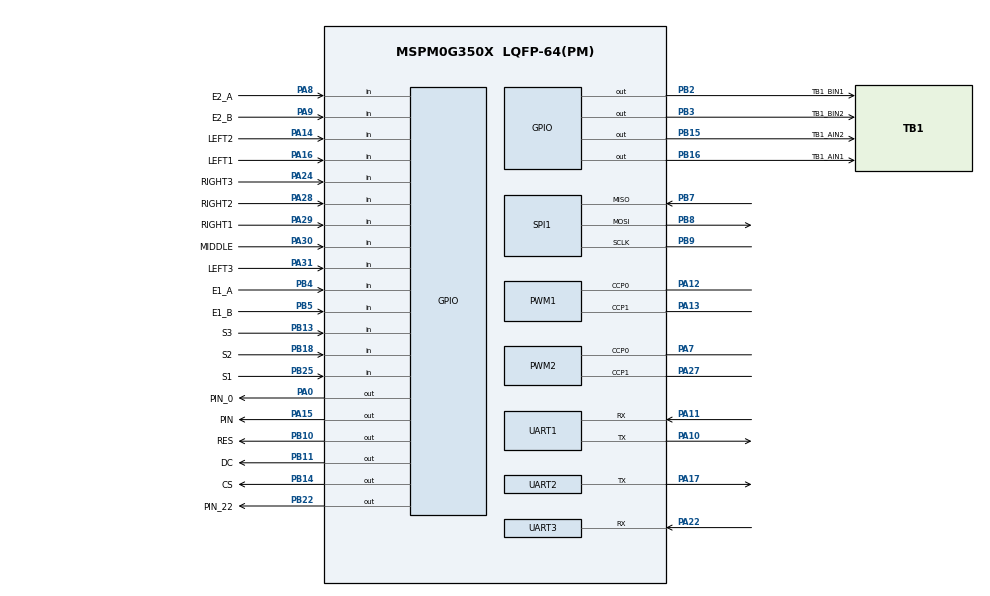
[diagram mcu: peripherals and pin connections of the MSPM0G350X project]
/**
 * @cliArgs --device "MSPM0G350X" --part "Default" --package "LQFP-64(PM)" --product "mspm0_sdk@2.05.01.01"
 * @versions {"tool":"1.24.0+4110"}
 */

/**
 * Import the modules used in this configuration.
 */
const GPIO    = scripting.addModule("/ti/driverlib/GPIO", {}, false);
const GPIO1   = GPIO.addInstance();
const GPIO2   = GPIO.addInstance();
const GPIO3   = GPIO.addInstance();
const GPIO4   = GPIO.addInstance();
const GPIO5   = GPIO.addInstance();
const GPIO6   = GPIO.addInstance();
const GPIO7   = GPIO.addInstance();
const GPIO8   = GPIO.addInstance();
const GPIO9   = GPIO.addInstance();
const PWM     = scripting.addModule("/ti/driverlib/PWM", {}, false);
const PWM1    = PWM.addInstance();
const PWM2    = PWM.addInstance();
const SPI     = scripting.addModule("/ti/driverlib/SPI", {}, false);
const SPI1    = SPI.addInstance();
const SYSCTL  = scripting.addModule("/ti/driverlib/SYSCTL");
const SYSTICK = scripting.addModule("/ti/driverlib/SYSTICK");
const TIMER   = scripting.addModule("/ti/driverlib/TIMER", {}, false);
const TIMER1  = TIMER.addInstance();
const TIMER2  = TIMER.addInstance();
const UART    = scripting.addModule("/ti/driverlib/UART", {}, false);
const UART1   = UART.addInstance();
const UART2   = UART.addInstance();
const UART3   = UART.addInstance();

/**
 * Write custom configuration values to the imported modules.
 */
const divider6       = system.clockTree["PLL_CLK2X_DIV"];
divider6.divideValue = 4;

const divider7       = system.clockTree["PLL_PDIV"];
divider7.divideValue = 2;

const divider9       = system.clockTree["UDIV"];
divider9.divideValue = 2;

const gate7  = system.clockTree["MFCLKGATE"];
gate7.enable = true;

const multiplier2         = system.clockTree["PLL_QDIV"];
multiplier2.multiplyValue = 10;

const mux8       = system.clockTree["HSCLKMUX"];
mux8.inputSelect = "HSCLKMUX_SYSPLL2X";

GPIO1.$name                         = "LED";
GPIO1.port                          = "PORTB";
GPIO1.associatedPins[0].$name       = "PIN_22";
GPIO1.associatedPins[0].ioStructure = "SD";
GPIO1.associatedPins[0].assignedPin = "22";
GPIO1.associatedPins[0].pin.$assign = "PB22";

const Board = scripting.addModule("/ti/driverlib/Board", {}, false);

GPIO2.$name                         = "OLED";
GPIO2.port                          = "PORTB";
GPIO2.associatedPins.create(3);
GPIO2.associatedPins[0].$name       = "RES";
GPIO2.associatedPins[0].assignedPin = "10";
GPIO2.associatedPins[0].pin.$assign = "PB10";
GPIO2.associatedPins[1].$name       = "DC";
GPIO2.associatedPins[1].assignedPin = "11\\";
GPIO2.associatedPins[1].pin.$assign = "PB11";
GPIO2.associatedPins[2].$name       = "CS";
GPIO2.associatedPins[2].assignedPin = "14";
GPIO2.associatedPins[2].pin.$assign = "PB14";

GPIO3.$name                              = "SW";
GPIO3.port                               = "PORTB";
GPIO3.associatedPins.create(3);
GPIO3.associatedPins[0].$name            = "S1";
GPIO3.associatedPins[0].direction        = "INPUT";
GPIO3.associatedPins[0].internalResistor = "PULL_UP";
GPIO3.associatedPins[0].assignedPin      = "25";
GPIO3.associatedPins[0].pin.$assign      = "PB25";
GPIO3.associatedPins[1].$name            = "S2";
GPIO3.associatedPins[1].direction        = "INPUT";
GPIO3.associatedPins[1].internalResistor = "PULL_UP";
GPIO3.associatedPins[1].assignedPin      = "18";
GPIO3.associatedPins[1].pin.$assign      = "PB18";
GPIO3.associatedPins[2].$name            = "S3";
GPIO3.associatedPins[2].direction        = "INPUT";
GPIO3.associatedPins[2].assignedPin      = "13";
GPIO3.associatedPins[2].internalResistor = "PULL_UP";
GPIO3.associatedPins[2].pin.$assign      = "PB13";

GPIO4.$name                         = "BUZZER";
GPIO4.port                          = "PORTA";
GPIO4.associatedPins[0].$name       = "PIN";
GPIO4.associatedPins[0].assignedPin = "15";
GPIO4.associatedPins[0].pin.$assign = "PA15";

GPIO5.$name                         = "TB6612_1";
GPIO5.port                          = "PORTB";
GPIO5.associatedPins.create(4);
GPIO5.associatedPins[0].$name       = "TB1_AIN2";
GPIO5.associatedPins[0].assignedPin = "15";
GPIO5.associatedPins[0].pin.$assign = "PB15";
GPIO5.associatedPins[1].$name       = "TB1_AIN1";
GPIO5.associatedPins[1].assignedPin = "16";
GPIO5.associatedPins[1].pin.$assign = "PB16";
GPIO5.associatedPins[2].$name       = "TB1_BIN1";
GPIO5.associatedPins[2].assignedPin = "2";
GPIO5.associatedPins[2].pin.$assign = "PB2";
GPIO5.associatedPins[3].$name       = "TB1_BIN2";
GPIO5.associatedPins[3].assignedPin = "3";
GPIO5.associatedPins[3].pin.$assign = "PB3";

GPIO6.$name                         = "Encoder1";
GPIO6.port                          = "PORTB";
GPIO6.associatedPins.create(2);
GPIO6.associatedPins[0].$name       = "E1_A";
GPIO6.associatedPins[0].direction   = "INPUT";
GPIO6.associatedPins[0].interruptEn = true;
GPIO6.associatedPins[0].polarity    = "RISE";
GPIO6.associatedPins[0].assignedPin = "4";
GPIO6.associatedPins[0].pin.$assign = "PB4";
GPIO6.associatedPins[1].$name       = "E1_B";
GPIO6.associatedPins[1].direction   = "INPUT";
GPIO6.associatedPins[1].assignedPin = "5";
GPIO6.associatedPins[1].interruptEn = true;
GPIO6.associatedPins[1].polarity    = "RISE";
GPIO6.associatedPins[1].pin.$assign = "PB5";

GPIO7.$name                         = "Encoder2";
GPIO7.port                          = "PORTA";
GPIO7.associatedPins.create(2);
GPIO7.associatedPins[0].$name       = "E2_A";
GPIO7.associatedPins[0].direction   = "INPUT";
GPIO7.associatedPins[0].assignedPin = "8";
GPIO7.associatedPins[0].interruptEn = true;
GPIO7.associatedPins[0].polarity    = "RISE";
GPIO7.associatedPins[0].pin.$assign = "PA8";
GPIO7.associatedPins[1].$name       = "E2_B";
GPIO7.associatedPins[1].direction   = "INPUT";
GPIO7.associatedPins[1].assignedPin = "9";
GPIO7.associatedPins[1].interruptEn = true;
GPIO7.associatedPins[1].polarity    = "RISE";
GPIO7.associatedPins[1].pin.$assign = "PA9";

GPIO8.$name                              = "GRAY";
GPIO8.port                               = "PORTA";
GPIO8.associatedPins.create(7);
GPIO8.associatedPins[0].$name            = "RIGHT2";
GPIO8.associatedPins[0].direction        = "INPUT";
GPIO8.associatedPins[0].internalResistor = "PULL_UP";
GPIO8.associatedPins[0].assignedPin      = "28";
GPIO8.associatedPins[0].pin.$assign      = "PA28";
GPIO8.associatedPins[1].$name            = "RIGHT1";
GPIO8.associatedPins[1].direction        = "INPUT";
GPIO8.associatedPins[1].internalResistor = "PULL_UP";
GPIO8.associatedPins[1].assignedPin      = "29";
GPIO8.associatedPins[1].pin.$assign      = "PA29";
GPIO8.associatedPins[2].$name            = "MIDDLE";
GPIO8.associatedPins[2].direction        = "INPUT";
GPIO8.associatedPins[2].internalResistor = "PULL_UP";
GPIO8.associatedPins[2].assignedPin      = "30";
GPIO8.associatedPins[2].pin.$assign      = "PA30";
GPIO8.associatedPins[3].$name            = "LEFT1";
GPIO8.associatedPins[3].direction        = "INPUT";
GPIO8.associatedPins[3].internalResistor = "PULL_UP";
GPIO8.associatedPins[3].assignedPin      = "16";
GPIO8.associatedPins[3].pin.$assign      = "PA16";
GPIO8.associatedPins[4].direction        = "INPUT";
GPIO8.associatedPins[4].internalResistor = "PULL_UP";
GPIO8.associatedPins[4].$name            = "LEFT2";
GPIO8.associatedPins[4].assignedPin      = "14";
GPIO8.associatedPins[4].pin.$assign      = "PA14";
GPIO8.associatedPins[5].$name            = "RIGHT3";
GPIO8.associatedPins[5].direction        = "INPUT";
GPIO8.associatedPins[5].internalResistor = "PULL_UP";
GPIO8.associatedPins[5].assignedPin      = "24";
GPIO8.associatedPins[5].pin.$assign      = "PA24";
GPIO8.associatedPins[6].$name            = "LEFT3";
GPIO8.associatedPins[6].direction        = "INPUT";
GPIO8.associatedPins[6].assignedPin      = "31";
GPIO8.associatedPins[6].internalResistor = "PULL_UP";
GPIO8.associatedPins[6].pin.$assign      = "PA31";

GPIO9.$name                         = "UV";
GPIO9.port                          = "PORTA";
GPIO9.associatedPins[0].$name       = "PIN_0";
GPIO9.associatedPins[0].assignedPin = "0";
GPIO9.associatedPins[0].pin.$assign = "PA0";

PWM1.$name                              = "TIMG0_PWM";
PWM1.clockPrescale                      = 2;
PWM1.timerStartTimer                    = true;
PWM1.timerCount                         = 100;
PWM1.clockDivider                       = 8;
PWM1.pwmMode                            = "EDGE_ALIGN_UP";
PWM1.peripheral.$assign                 = "TIMG0";
PWM1.peripheral.ccp0Pin.$assign         = "PA12";
PWM1.peripheral.ccp1Pin.$assign         = "PA13";
PWM1.PWM_CHANNEL_0.$name                = "ti_driverlib_pwm_PWMTimerCC0";
PWM1.PWM_CHANNEL_1.$name                = "ti_driverlib_pwm_PWMTimerCC1";
PWM1.ccp0PinConfig.direction            = scripting.forceWrite("OUTPUT");
PWM1.ccp0PinConfig.hideOutputInversion  = scripting.forceWrite(false);
PWM1.ccp0PinConfig.onlyInternalResistor = scripting.forceWrite(false);
PWM1.ccp0PinConfig.passedPeripheralType = scripting.forceWrite("Digital");
PWM1.ccp0PinConfig.$name                = "ti_driverlib_gpio_GPIOPinGeneric6";
PWM1.ccp1PinConfig.direction            = scripting.forceWrite("OUTPUT");
PWM1.ccp1PinConfig.hideOutputInversion  = scripting.forceWrite(false);
PWM1.ccp1PinConfig.onlyInternalResistor = scripting.forceWrite(false);
PWM1.ccp1PinConfig.passedPeripheralType = scripting.forceWrite("Digital");
PWM1.ccp1PinConfig.$name                = "ti_driverlib_gpio_GPIOPinGeneric7";

PWM2.timerStartTimer                    = true;
PWM2.clockDivider                       = 8;
PWM2.clockPrescale                      = 100;
PWM2.pwmMode                            = "EDGE_ALIGN_UP";
PWM2.$name                              = "TIMG8_PWM";
PWM2.peripheral.$assign                 = "TIMG8";
PWM2.peripheral.ccp0Pin.$assign         = "PA7";
PWM2.peripheral.ccp1Pin.$assign         = "PA27";
PWM2.PWM_CHANNEL_0.$name                = "ti_driverlib_pwm_PWMTimerCC2";
PWM2.PWM_CHANNEL_0.dutyCycle            = 40;
PWM2.PWM_CHANNEL_1.$name                = "ti_driverlib_pwm_PWMTimerCC3";
PWM2.PWM_CHANNEL_1.dutyCycle            = 60;
PWM2.ccp0PinConfig.direction            = scripting.forceWrite("OUTPUT");
PWM2.ccp0PinConfig.hideOutputInversion  = scripting.forceWrite(false);
PWM2.ccp0PinConfig.onlyInternalResistor = scripting.forceWrite(false);
PWM2.ccp0PinConfig.passedPeripheralType = scripting.forceWrite("Digital");
PWM2.ccp0PinConfig.$name                = "ti_driverlib_gpio_GPIOPinGeneric8";
PWM2.ccp1PinConfig.direction            = scripting.forceWrite("OUTPUT");
PWM2.ccp1PinConfig.hideOutputInversion  = scripting.forceWrite(false);
PWM2.ccp1PinConfig.onlyInternalResistor = scripting.forceWrite(false);
PWM2.ccp1PinConfig.passedPeripheralType = scripting.forceWrite("Digital");
PWM2.ccp1PinConfig.$name                = "ti_driverlib_gpio_GPIOPinGeneric10";

SPI1.$name                              = "SPI_OLED";
SPI1.frameFormat                        = "MOTO3";
SPI1.sclkPinConfig.direction            = scripting.forceWrite("OUTPUT");
SPI1.sclkPinConfig.onlyInternalResistor = scripting.forceWrite(false);
SPI1.sclkPinConfig.passedPeripheralType = scripting.forceWrite("Digital");
SPI1.sclkPinConfig.$name                = "ti_driverlib_gpio_GPIOPinGeneric3";
SPI1.mosiPinConfig.direction            = scripting.forceWrite("OUTPUT");
SPI1.mosiPinConfig.hideOutputInversion  = scripting.forceWrite(false);
SPI1.mosiPinConfig.onlyInternalResistor = scripting.forceWrite(false);
SPI1.mosiPinConfig.passedPeripheralType = scripting.forceWrite("Digital");
SPI1.mosiPinConfig.$name                = "ti_driverlib_gpio_GPIOPinGeneric4";
SPI1.misoPinConfig.onlyInternalResistor = scripting.forceWrite(false);
SPI1.misoPinConfig.passedPeripheralType = scripting.forceWrite("Digital");
SPI1.misoPinConfig.$name                = "ti_driverlib_gpio_GPIOPinGeneric5";
SPI1.peripheral.$assign                 = "SPI1";
SPI1.peripheral.sclkPin.$assign         = "PB9";
SPI1.peripheral.mosiPin.$assign         = "PB8";
SPI1.peripheral.misoPin.$assign         = "PB7";

SYSCTL.forceDefaultClkConfig = true;
SYSCTL.clockTreeEn           = true;
scripting.suppress("For best practices when the CPUCLK is running at 32MHz and above, clear the flash status bit using DL_FlashCTL_executeClearStatus\\(\\) before executing any flash operation\\. Otherwise there may be false positives\\.", SYSCTL);

SYSTICK.periodEnable      = true;
SYSTICK.period            = 32000;
SYSTICK.interruptEnable   = true;
SYSTICK.systickEnable     = true;
SYSTICK.interruptPriority = "0";

TIMER1.$name              = "TIMA0_IC";
TIMER1.timerMode          = "PERIODIC";
TIMER1.timerClkDiv        = 8;
TIMER1.timerClkPrescale   = 8;
TIMER1.timerPeriod        = "20ms";
TIMER1.timerStartTimer    = true;
TIMER1.interrupts         = ["ZERO"];
TIMER1.peripheral.$assign = "TIMA0";

TIMER2.$name              = "TIMA1_IT";
TIMER2.timerStartTimer    = true;
TIMER2.timerClkPrescale   = 32;
TIMER2.timerClkDiv        = 2;
TIMER2.interrupts         = ["ZERO"];
TIMER2.timerMode          = "PERIODIC";
TIMER2.timerPeriod        = "1 ms";
TIMER2.peripheral.$assign = "TIMA1";

UART1.$name                    = "UART_0";
UART1.enabledInterrupts        = ["RX"];
UART1.uartClkSrc               = "MFCLK";
UART1.peripheral.$assign       = "UART0";
UART1.peripheral.rxPin.$assign = "PA11";
UART1.peripheral.txPin.$assign = "PA10";
UART1.txPinConfig.$name        = "ti_driverlib_gpio_GPIOPinGeneric0";
UART1.rxPinConfig.$name        = "ti_driverlib_gpio_GPIOPinGeneric1";

UART2.$name                    = "UART_1";
UART2.uartClkSrc               = "MFCLK";
UART2.direction                = "TX";
UART2.txPinConfig.$name        = "ti_driverlib_gpio_GPIOPinGeneric2";
UART2.peripheral.$assign       = "UART1";
UART2.peripheral.txPin.$assign = "PA17";

UART3.$name                    = "UART_2";
UART3.uartClkSrc               = "MFCLK";
UART3.direction                = "RX";
UART3.enabledInterrupts        = ["RX"];
UART3.rxPinConfig.$name        = "ti_driverlib_gpio_GPIOPinGeneric9";
UART3.peripheral.$assign       = "UART2";
UART3.peripheral.rxPin.$assign = "PA22";

/**
 * Pinmux solution for unlocked pins/peripherals. This ensures that minor changes to the automatic solver in a future
 * version of the tool will not impact the pinmux you originally saw.  These lines can be completely deleted in order to
 * re-solve from scratch.
 */
Board.peripheral.$suggestSolution          = "DEBUGSS";
Board.peripheral.swclkPin.$suggestSolution = "PA20";
Board.peripheral.swdioPin.$suggestSolution = "PA19";
